# ADuCM362 register map
Vendor: Analog Devices Inc.; Series: ADuCM36x; File version: 0.1
CPU: CM3 r2p1, little endian, no MPU, no FPU, 3 interrupt priority bits
Registers are 16-bit, read-write, no defined reset value unless marked. A register's access mark holds for its fields unless they carry their own. Offsets are from the block's base; [hi:lo] are bit positions; {n}, {i} and the like mark numbered series; 'fields as' and 'values as' point back to an identical list.

## ADI_CLKCTL — Clock Control
Base 0x40002000
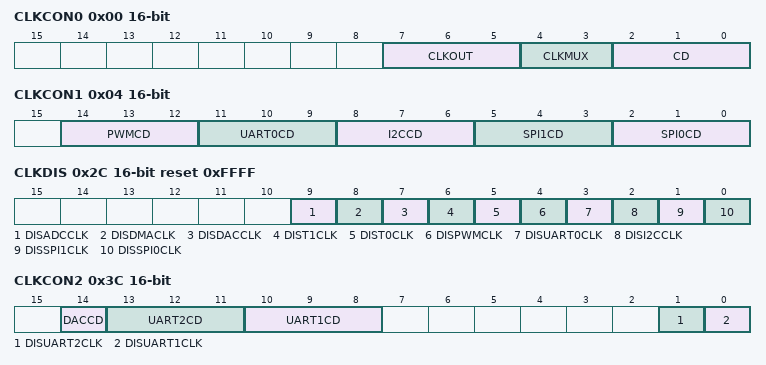
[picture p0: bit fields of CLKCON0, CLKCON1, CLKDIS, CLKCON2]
0x00 CLKCON0 — System clocking architecture control register
  [7:5] CLKOUT — GPIO output clock multiplexer select bits
    0=UCLKCG; 1=UCLK; 2=PCLK; 5=HFOSC; 6=LFOSC; 7=LFXTAL
  [4:3] CLKMUX — Digital subsystem clock source select bits.
    0=HFOSC; 1=LFXTAL; 2=LFOSC; 3=EXTCLK
  [2:0] CD — Clock divide bits
    0=DIV1; 1=DIV2; 2=DIV4; 3=DIV8; 4=DIV16; 5=DIV32; 6=DIV64; 7=DIV128
0x04 CLKCON1 — System Clocks Control Register 1
  [all] fields
    values as CLKCON0.CD
  [14:12] PWMCD — Clock divide bits for PWM system clock
  [11:9] UART0CD — Clock divide bits for UART0 system clock
  [8:6] I2CCD — Clock divide bits for I2C system clock
  [5:3] SPI1CD — Clock divide bits for SPI1 system clock
  [2:0] SPI0CD — Clock divide bits for SPI0 system clock
0x2C CLKDIS reset 0xFFFF (reset mask 0x0) — System Clocks Control Register 1
  [all] fields
    0=DIS; 1=EN
  [9] DISADCCLK — Disable ADC system clock
  [8] DISDMACLK — Disable DMA system clock
  [7] DISDACCLK — Disable DAC system clock
  [6] DIST1CLK — Disable Timer 1 system clock
  [5] DIST0CLK — Disable Timer 0 system clock
  [4] DISPWMCLK — Disable PWM system clock
  [3] DISUART0CLK — Disable UART0 system clock
  [2] DISI2CCLK — Disable I2C system clock
  [1] DISSPI1CLK — Disable SPI1 system clock
  [0] DISSPI0CLK — Disable SPI0 system clock bits
0x3C CLKCON2 — System Clocks Control Register 2
  [14] DACCD — Clock divide bits for DAC system clock
    0=DIV8; 1=DIV16
  [13:11] UART2CD — Clock divide bits for UART2 system clock
    values as CLKCON0.CD
  [10:8] UART1CD — Clock divide bits for UART1 system clock
    values as CLKCON0.CD
  [1] DISUART2CLK — Disable UART2 system clock
    0=DIS; 1=EN
  [0] DISUART1CLK — Disable UART1 system clock
    0=DIS; 1=EN
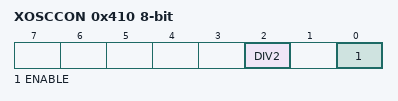
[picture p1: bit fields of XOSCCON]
0x410 XOSCCON 8-bit — Crystal Oscillator control
  [2] DIV2 — Divide by two enable
    0=DIS; 1=EN
  [0] ENABLE — Crystal oscillator circuit enable (Enable the oscillator circuitry.)
    0=DIS; 1=EN
0x444 CLKSYSDIV — Sys Clock div Register
  [1:0] CLKSEL — Clock divide bits for root system clock
    0=DIV1; 1=DIV2; 2=DIV4; 3=DIV8

## ADI_FEE — Flash Controller
Base 0x40002800
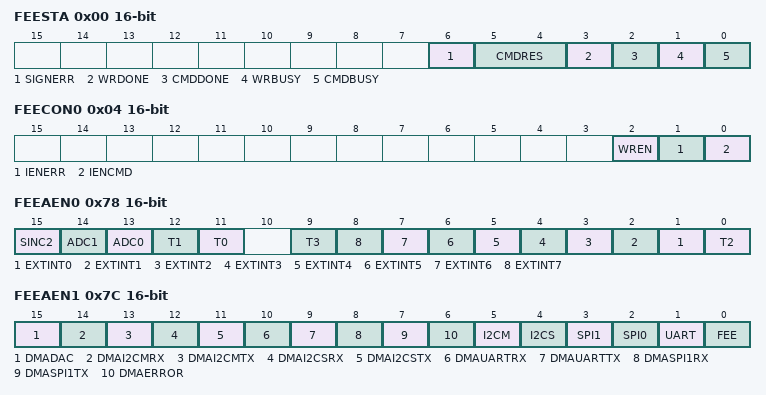
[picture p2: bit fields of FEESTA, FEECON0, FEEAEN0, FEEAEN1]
0x00 FEESTA ro — Status Register
  [6] SIGNERR — Info space signature check on reset error
    0=CLR; 1=SET
  [5:4] CMDRES — Command result
    0=SUCCESS; 1=PROTECTED; 2=VERIFYERR; 3=ABORT
  [3] WRDONE — Write Complete
    0=CLR; 1=SET
  [2] CMDDONE — Command complete
    0=CLR; 1=SET
  [1] WRBUSY — Write busy
    0=CLR; 1=SET
  [0] CMDBUSY — Command busy
    0=CLR; 1=SET
0x04 FEECON0 — Command Control Register
  [all] fields
    0=DIS; 1=EN
  [2] WREN — Write enable.
  [1] IENERR — Error interrupt enable
  [0] IENCMD — Command complete interrupt enable
0x08 FEECMD — Command register
  [3:0] CMD — Command
    0=IDLE (- No command executed); 1=ERASEPAGE; 2=SIGN (- Sign Range); 3=MASSERASE (- Mass Erase User Space); 4=ABORT (- Abort a running command)
0x10 FEEADR0L — Low Page (Lower 16 bits)
  [15:0] VALUE range 0x00000000..0x0000FFFF
0x14 FEEADR0H — Low Page (Upper 16 bits)
  [1:0] VALUE range 0x00000000..0x00000003
0x18 FEEADR1L — Hi Page (Lower 16 bits)
  [15:0] VALUE range 0x00000000..0x0000FFFF
0x1C FEEADR1H — Hi Page (Upper 16 bits)
  [1:0] VALUE range 0x00000000..0x00000003
0x20 FEEKEY wo — Key
  [15:0] VALUE
    0xF456=USERKEY1; 0xF123=USERKEY2
0x28 FEEPROL reset 0xFFFF (reset mask 0x0) — Write Protection (Lower 16 bits)
  [15:0] VALUE range 0x00000000..0x0000FFFF
0x2C FEEPROH reset 0xFFFF (reset mask 0x0) — Write Protection (Upper 16 bits)
  [15:0] VALUE range 0x00000000..0x0000FFFF
0x30 FEESIGL ro reset 0xFFFF (reset mask 0x0) — Signature (Lower 16 bits)
  [15:0] VALUE range 0x00000000..0x0000FFFF
0x34 FEESIGH ro reset 0xFFFF (reset mask 0x0) — Signature (Upper 16 bits)
  [7:0] VALUE range 0x00000000..0x000000FF
0x38 FEECON1 reset 0x1 (reset mask 0x0) — User Setup register
  [0] DBG — Serial Wire debug enable ,
    0=DIS; 1=EN
0x48 FEEADRAL ro reset 0x800 (reset mask 0x0) — Abort address (Lower 16 bits)
  [15:0] VALUE range 0x00000000..0x0000FFFF
0x4C FEEADRAH ro reset 0x2 (reset mask 0x0) — Abort address (Upper 16 bits)
  [15:0] VALUE range 0x00000000..0x0000FFFF
0x78 FEEAEN0 — Lower 16 bits of the sys irq abort enable register.
  [all] fields
    0=DIS; 1=EN
  [15] SINC2
  [14] ADC1
  [13] ADC0
  [12] T1
  [11] T0
  [9] T3
  [n+1] EXTINT{n} (n=0..7)
  [0] T2
0x7C FEEAEN1 — Upper 16 bits of the sys irq abort enable register.
  [all] fields
    0=DIS; 1=EN
  [15] DMADAC
  [14] DMAI2CMRX
  [13] DMAI2CMTX
  [12] DMAI2CSRX
  [11] DMAI2CSTX
  [10] DMAUARTRX
  [9] DMAUARTTX
  [8] DMASPI1RX
  [7] DMASPI1TX
  [6] DMAERROR
  [5] I2CM
  [4] I2CS
  [3] SPI1
  [2] SPI0
  [1] UART
  [0] FEE
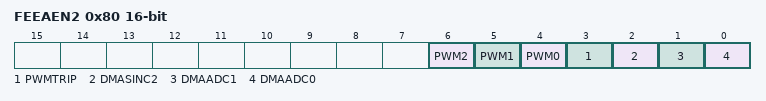
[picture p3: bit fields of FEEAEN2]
0x80 FEEAEN2 — Upper 32..47 bits of the sys irq abort enable register.
  [all] fields
    0=DIS; 1=EN
  [6] PWM2
  [5] PWM1
  [4] PWM0
  [3] PWMTRIP
  [2] DMASINC2
  [1] DMAADC1
  [0] DMAADC0
